# STM32H757_CM4 register map
File version: 2.3
CPU: CM4 r0p1, little endian, MPU, FPU, 4 interrupt priority bits
Registers are 32-bit, read-write, reset 0x0 unless marked. A register's access mark holds for its fields unless they carry their own. Offsets are from the block's base; [hi:lo] are bit positions.

## IWDG1 — IWDG
Base 0x58004800
Same registers: IWDG2 0x58004C00
0x00 KR 16-bit wo — Key register
  [15:0] KEY — Key value (write only, read 0x0000) These bits must be written by software at regular intervals with the key value 0xAAAA, otherwise the watchdog generates a reset when the counter reaches 0. Writing the key value 0x5555 to enable access to the IWDG_PR, IWDG_RLR and IWDG_WINR registers (see Section23.3.6: Register access protection) Writing the key value CCCCh starts the watchdog (except if the hardware watchdog option is selected)
    0x5555=Unlock (Enable access to PR, RLR and WINR registers); 0xAAAA=Feed watchdog with RLR register value; 0xCCCC=Start the watchdog
0x04 PR 16-bit — Prescaler register
  [2:0] PR — Prescaler divider These bits are write access protected see Section23.3.6: Register access protection. They are written by software to select the prescaler divider feeding the counter clock. PVU bit of IWDG_SR must be reset in order to be able to change the prescaler divider. Note: Reading this register returns the prescaler value from the VDD voltage domain. This value may not be up to date/valid if a write operation to this register is ongoing. For this reason the value read from this register is valid only when the PVU bit in the IWDG_SR register is reset.
    0=DivideBy4 (Divider /4); 1=DivideBy8 (Divider /8); 2=DivideBy16 (Divider /16); 3=DivideBy32 (Divider /32); 4=DivideBy64 (Divider /64); 5=DivideBy128 (Divider /128); other=DivideBy256 (Divider /256)
0x08 RLR 16-bit reset 0xFFF — Reload register
  [11:0] RL — Watchdog counter reload value These bits are write access protected see Section23.3.6. They are written by software to define the value to be loaded in the watchdog counter each time the value 0xAAAA is written in the IWDG_KR register. The watchdog counter counts down from this value. The timeout period is a function of this value and the clock prescaler. Refer to the datasheet for the timeout information. The RVU bit in the IWDG_SR register must be reset in order to be able to change the reload value. Note: Reading this register returns the reload value from the VDD voltage domain. This value may not be up to date/valid if a write operation to this register is ongoing on this register. For this reason the value read from this register is valid only when the RVU bit in the IWDG_SR register is reset.
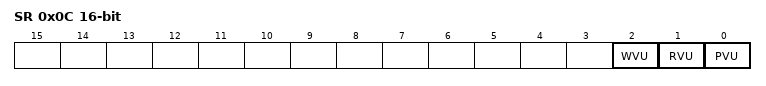
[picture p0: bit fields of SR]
0x0C SR 16-bit ro — Status register
  [2] WVU — Watchdog counter window value update This bit is set by hardware to indicate that an update of the window value is ongoing. It is reset by hardware when the reload value update operation is completed in the VDD voltage domain (takes up to 5 RC 40 kHz cycles). Window value can be updated only when WVU bit is reset. This bit is generated only if generic window = 1
  [1] RVU — Watchdog counter reload value update This bit is set by hardware to indicate that an update of the reload value is ongoing. It is reset by hardware when the reload value update operation is completed in the VDD voltage domain (takes up to 5 RC 40 kHz cycles). Reload value can be updated only when RVU bit is reset.
  [0] PVU — Watchdog prescaler value update This bit is set by hardware to indicate that an update of the prescaler value is ongoing. It is reset by hardware when the prescaler update operation is completed in the VDD voltage domain (takes up to 5 RC 40 kHz cycles). Prescaler value can be updated only when PVU bit is reset.
0x10 WINR 16-bit reset 0xFFF — Window register
  [11:0] WIN — Watchdog counter window value These bits are write access protected see Section23.3.6. These bits contain the high limit of the window value to be compared to the downcounter. To prevent a reset, the downcounter must be reloaded when its value is lower than the window register value and greater than 0x0 The WVU bit in the IWDG_SR register must be reset in order to be able to change the reload value. Note: Reading this register returns the reload value from the VDD voltage domain. This value may not be valid if a write operation to this register is ongoing. For this reason the value read from this register is valid only when the WVU bit in the IWDG_SR register is reset.
